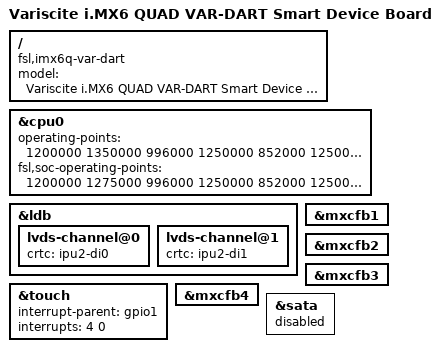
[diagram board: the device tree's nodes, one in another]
/*
 * Copyright (C) 2015-2017 Variscite Ltd.
 *
 * This program is free software; you can redistribute it and/or modify
 * it under the terms of the GNU General Public License version 2 as
 * published by the Free Software Foundation.
 */

/dts-v1/;

#include "imx6q.dtsi"
#include "imx6qdl-var-dart.dtsi"
#include "imx6qdl-var-solocb-dt6cb-displays.dtsi"
#include "imx6qdl-var-dt6cb-buttons.dtsi"

/ {
	model = "Variscite i.MX6 QUAD VAR-DART Smart Device Board";
	compatible = "fsl,imx6q-var-dart", "fsl,imx6q";
};

&cpu0 {
	operating-points = <
		/* kHz    uV */
		1200000	1350000
		996000	1250000
		852000	1250000
		792000	1175000
		396000	1175000
	>;
	fsl,soc-operating-points = <
		/* ARM kHz  SOC-PU uV */
		1200000	1275000
		996000	1250000
		852000	1250000
		792000	1250000
		396000	1250000
	>;
};

&ldb {
	lvds-channel@0 {
		crtc = "ipu2-di0";
	};

	lvds-channel@1 {
		crtc = "ipu2-di1";
	};
};

&touch {
	interrupt-parent = <&gpio1>;
	interrupts = <4 0>;
};

&mxcfb1 {
	status = "okay";
};

&mxcfb2 {
	status = "okay";
};

&mxcfb3 {
	status = "okay";
};

&mxcfb4 {
	status = "okay";
};

&sata {
	status = "disabled";
};
